# STM32F407 register map
File version: 1.2
CPU: CM4 r1p0, little endian, no MPU, no FPU, 4 interrupt priority bits
Registers are 32-bit, read-write, reset 0x0 unless marked. A register's access mark holds for its fields unless they carry their own. Offsets are from the block's base; [hi:lo] are bit positions; lines under a group give offsets from that group; {n}, {i} and the like mark numbered series.

## OTG_HS_PWRCLK — USB on the go high speed
Base 0x40040E00
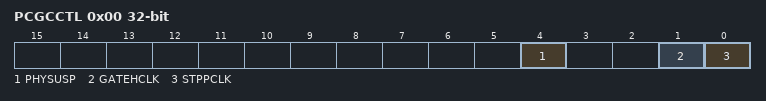
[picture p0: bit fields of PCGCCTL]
0x00 PCGCCTL — Power and clock gating control register
  [4] PHYSUSP — PHY suspended
  [1] GATEHCLK
  [0] STPPCLK — Stop PHY clock

## NVIC — Nested Vectored Interrupt Controller
Base 0xE000E100
{0x0+4i} ISER{i} (i=0..2) — Interrupt Set-Enable Register
  [31:0] SETENA
{0x80+4i} ICER{i} (i=0..2) — Interrupt Clear-Enable Register
  [31:0] CLRENA
{0x100+4i} ISPR{i} (i=0..2) — Interrupt Set-Pending Register
  [31:0] SETPEND
{0x180+4i} ICPR{i} (i=0..2) — Interrupt Clear-Pending Register
  [31:0] CLRPEND
{0x200+4i} IABR{i} ro (i=0..2) — Interrupt Active Bit Register
  [31:0] ACTIVE
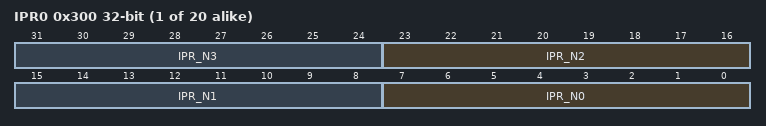
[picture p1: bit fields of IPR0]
{0x300+4i} IPR{i} (i=0..19) — Interrupt Priority Register
  [8n+7:8n] IPR_N{n} (n=0..3)

## HASH — Hash processor
Base 0x50060400
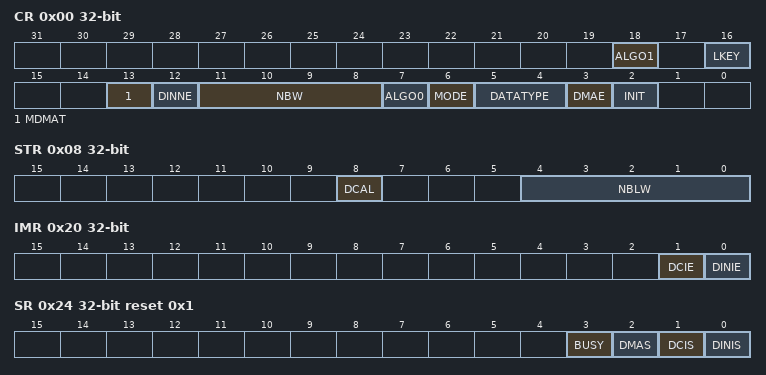
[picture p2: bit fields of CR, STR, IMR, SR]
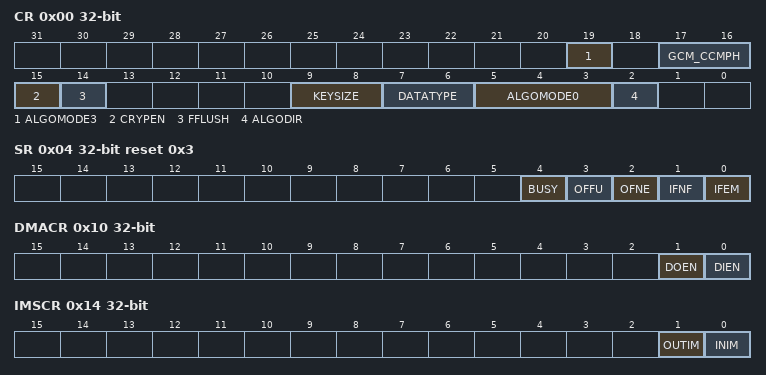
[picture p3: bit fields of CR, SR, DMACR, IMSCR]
0x00 CR access per field — control register
  [18] ALGO1 rw — ALGO
  [16] LKEY rw — Long key selection
  [13] MDMAT rw — Multiple DMA Transfers
  [12] DINNE ro — DIN not empty
  [11:8] NBW ro — Number of words already pushed
  [7] ALGO0 rw — Algorithm selection
  [6] MODE rw — Mode selection
  [5:4] DATATYPE rw — Data type selection
  [3] DMAE rw — DMA enable
  [2] INIT wo — Initialize message digest calculation
0x04 DIN — data input register
  [31:0] DATAIN — Data input
0x08 STR access per field — start register
  [8] DCAL wo — Digest calculation
  [4:0] NBLW rw — Number of valid bits in the last word of the message
{0xC+4i} HR{i} (i=0..4) ro — digest registers
  [31:0] H — H0
0x20 IMR — interrupt enable register
  [1] DCIE — Digest calculation completion interrupt enable
  [0] DINIE — Data input interrupt enable
0x24 SR access per field reset 0x1 — status register
  [3] BUSY ro — Busy bit
  [2] DMAS ro — DMA Status
  [1] DCIS rw — Digest calculation completion interrupt status
  [0] DINIS rw — Data input interrupt status
{0xF8+4i} CSR{i} (i=0..53) — context swap registers
  [31:0] CSR — CSR0
{0x310+4i} HASH_HR{i} (i=0..7) ro — HASH digest register
  [31:0] H — H0

## CRYP — Cryptographic processor
Base 0x50060000
0x00 CR access per field — control register
  [19] ALGOMODE3 rw — ALGOMODE
  [17:16] GCM_CCMPH rw
  [15] CRYPEN rw — Cryptographic processor enable
  [14] FFLUSH wo — FIFO flush
  [9:8] KEYSIZE rw — Key size selection (AES mode only)
  [7:6] DATATYPE rw — Data type selection
  [5:3] ALGOMODE0 rw — Algorithm mode
  [2] ALGODIR rw — Algorithm direction
0x04 SR ro reset 0x3 — status register
  [4] BUSY — Busy bit
  [3] OFFU — Output FIFO full
  [2] OFNE — Output FIFO not empty
  [1] IFNF — Input FIFO not full
  [0] IFEM — Input FIFO empty
0x08 DIN — data input register
  [31:0] DATAIN — Data input
0x0C DOUT ro — data output register
  [31:0] DATAOUT — Data output
0x10 DMACR — DMA control register
  [1] DOEN — DMA output enable
  [0] DIEN — DMA input enable
0x14 IMSCR — interrupt mask set/clear register
  [1] OUTIM — Output FIFO service interrupt mask
  [0] INIM — Input FIFO service interrupt mask
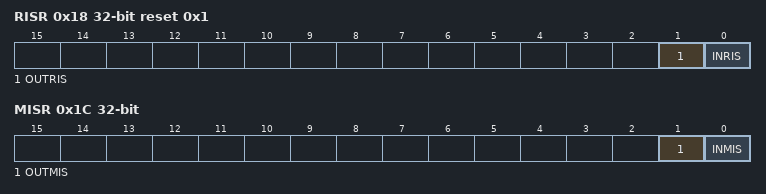
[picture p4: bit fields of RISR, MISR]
0x18 RISR ro reset 0x1 — raw interrupt status register
  [1] OUTRIS — Output FIFO service raw interrupt status
  [0] INRIS — Input FIFO service raw interrupt status
0x1C MISR ro — masked interrupt status register
  [1] OUTMIS — Output FIFO service masked interrupt status
  [0] INMIS — Input FIFO service masked interrupt status
{0x20+8i} KEY{i} (i=0..3) group — Cluster KEY{i}, containing K?LR, K?RR
  0x00 KLR wo — key registers
    [31:0] b2 — b224
  0x04 KRR wo — key registers
    [31:0] b — b192
{0x40+8i} INIT{i} (i=0..1) group — Cluster INIT{i}, containing IV?LR, IV?RR
  0x00 IVLR — initialization vector registers
    [31:0] IV — IV31
  0x04 IVRR — initialization vector registers
    [31:0] IV — IV63
{0x50+4i} CSGCMCCM{i}R (i=0..7) — context swap register
  [31:0] CSGCMCCM0R
{0x70+4i} CSGCM{i}R (i=0..7) — context swap register
  [31:0] CSGCMR — CSGCM0R

## FPU — Floting point unit
Base 0xE000EF34
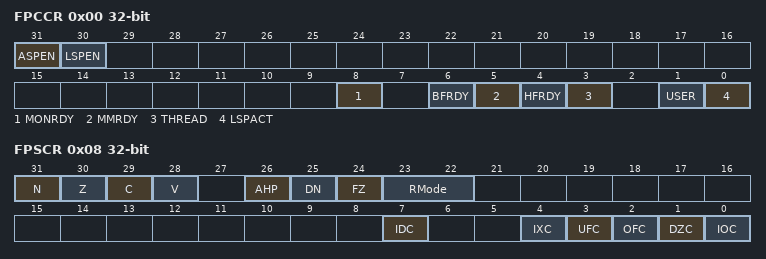
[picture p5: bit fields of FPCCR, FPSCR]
0x00 FPCCR — Floating-point context control register
  [31] ASPEN, [30] LSPEN, [8] MONRDY, [6] BFRDY, [5] MMRDY, [4] HFRDY, [3] THREAD, [1] USER, [0] LSPACT
0x04 FPCAR — Floating-point context address register
  [31:3] ADDRESS — Location of unpopulated floating-point
0x08 FPSCR — Floating-point status control register
  [31] N — Negative condition code flag
  [30] Z — Zero condition code flag
  [29] C — Carry condition code flag
  [28] V — Overflow condition code flag
  [26] AHP — Alternative half-precision control bit
  [25] DN — Default NaN mode control bit
  [24] FZ — Flush-to-zero mode control bit:
  [23:22] RMode — Rounding Mode control field
  [7] IDC — Input denormal cumulative exception bit.
  [4] IXC — Inexact cumulative exception bit
  [3] UFC — Underflow cumulative exception bit
  [2] OFC — Overflow cumulative exception bit
  [1] DZC — Division by zero cumulative exception bit.
  [0] IOC — Invalid operation cumulative exception bit

## MPU — Memory protection unit
Base 0xE000ED90
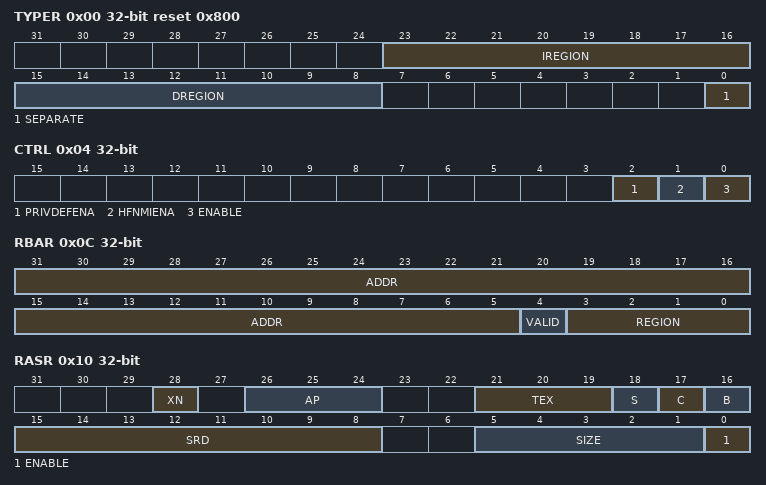
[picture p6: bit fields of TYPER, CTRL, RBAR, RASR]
0x00 TYPER ro reset 0x800 — MPU type register
  [23:16] IREGION — Number of MPU instruction regions
  [15:8] DREGION — Number of MPU data regions
  [0] SEPARATE — Separate flag
0x04 CTRL ro — MPU control register
  [2] PRIVDEFENA — Enable priviliged software access to default memory map
  [1] HFNMIENA — Enables the operation of MPU during hard fault
  [0] ENABLE — Enables the MPU
0x08 RNR — MPU region number register
  [7:0] REGION — MPU region
0x0C RBAR — MPU region base address register
  [31:5] ADDR — Region base address field
  [4] VALID — MPU region number valid
  [3:0] REGION — MPU region field
0x10 RASR — MPU region attribute and size register
  [28] XN — Instruction access disable bit
  [26:24] AP — Access permission
  [21:19] TEX — memory attribute
  [18] S — Shareable memory attribute
  [17] C — memory attribute
  [16] B — memory attribute
  [15:8] SRD — Subregion disable bits
  [5:1] SIZE — Size of the MPU protection region
  [0] ENABLE — Region enable bit.

## STK — SysTick timer
Base 0xE000E010
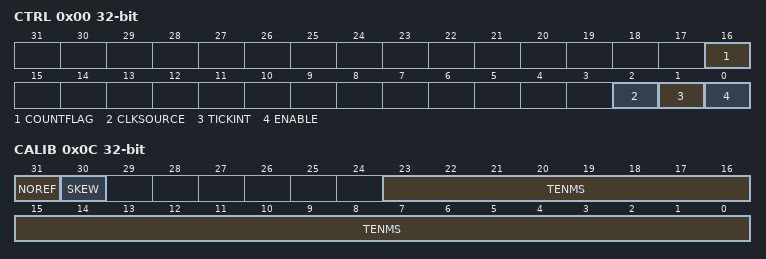
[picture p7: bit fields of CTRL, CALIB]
0x00 CTRL — SysTick control and status register
  [16] COUNTFLAG
  [2] CLKSOURCE — Clock source selection
  [1] TICKINT — SysTick exception request enable
  [0] ENABLE — Counter enable
0x04 LOAD — SysTick reload value register
  [23:0] RELOAD — RELOAD value
0x08 VAL — SysTick current value register
  [23:0] CURRENT — Current counter value
0x0C CALIB — SysTick calibration value register
  [31] NOREF — NOREF flag. Reads as zero
  [30] SKEW — SKEW flag: Indicates whether the TENMS value is exact
  [23:0] TENMS — Calibration value

## NVIC_STIR — Nested vectored interrupt controller
Base 0xE000EF00
0x00 STIR — Software trigger interrupt register
  [8:0] INTID — Software generated interrupt ID

## FPU_CPACR — Floating point unit CPACR
Base 0xE000ED88
0x00 CPACR — Coprocessor access control register
  [23:20] CP

## SCB_ACTRL — System control block ACTLR
Base 0xE000E008
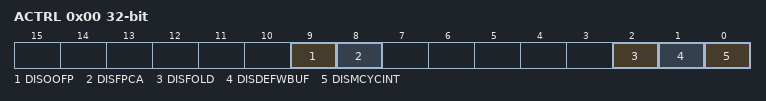
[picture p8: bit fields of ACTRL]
0x00 ACTRL — Auxiliary control register
  [9] DISOOFP, [8] DISFPCA, [2] DISFOLD, [1] DISDEFWBUF, [0] DISMCYCINT
